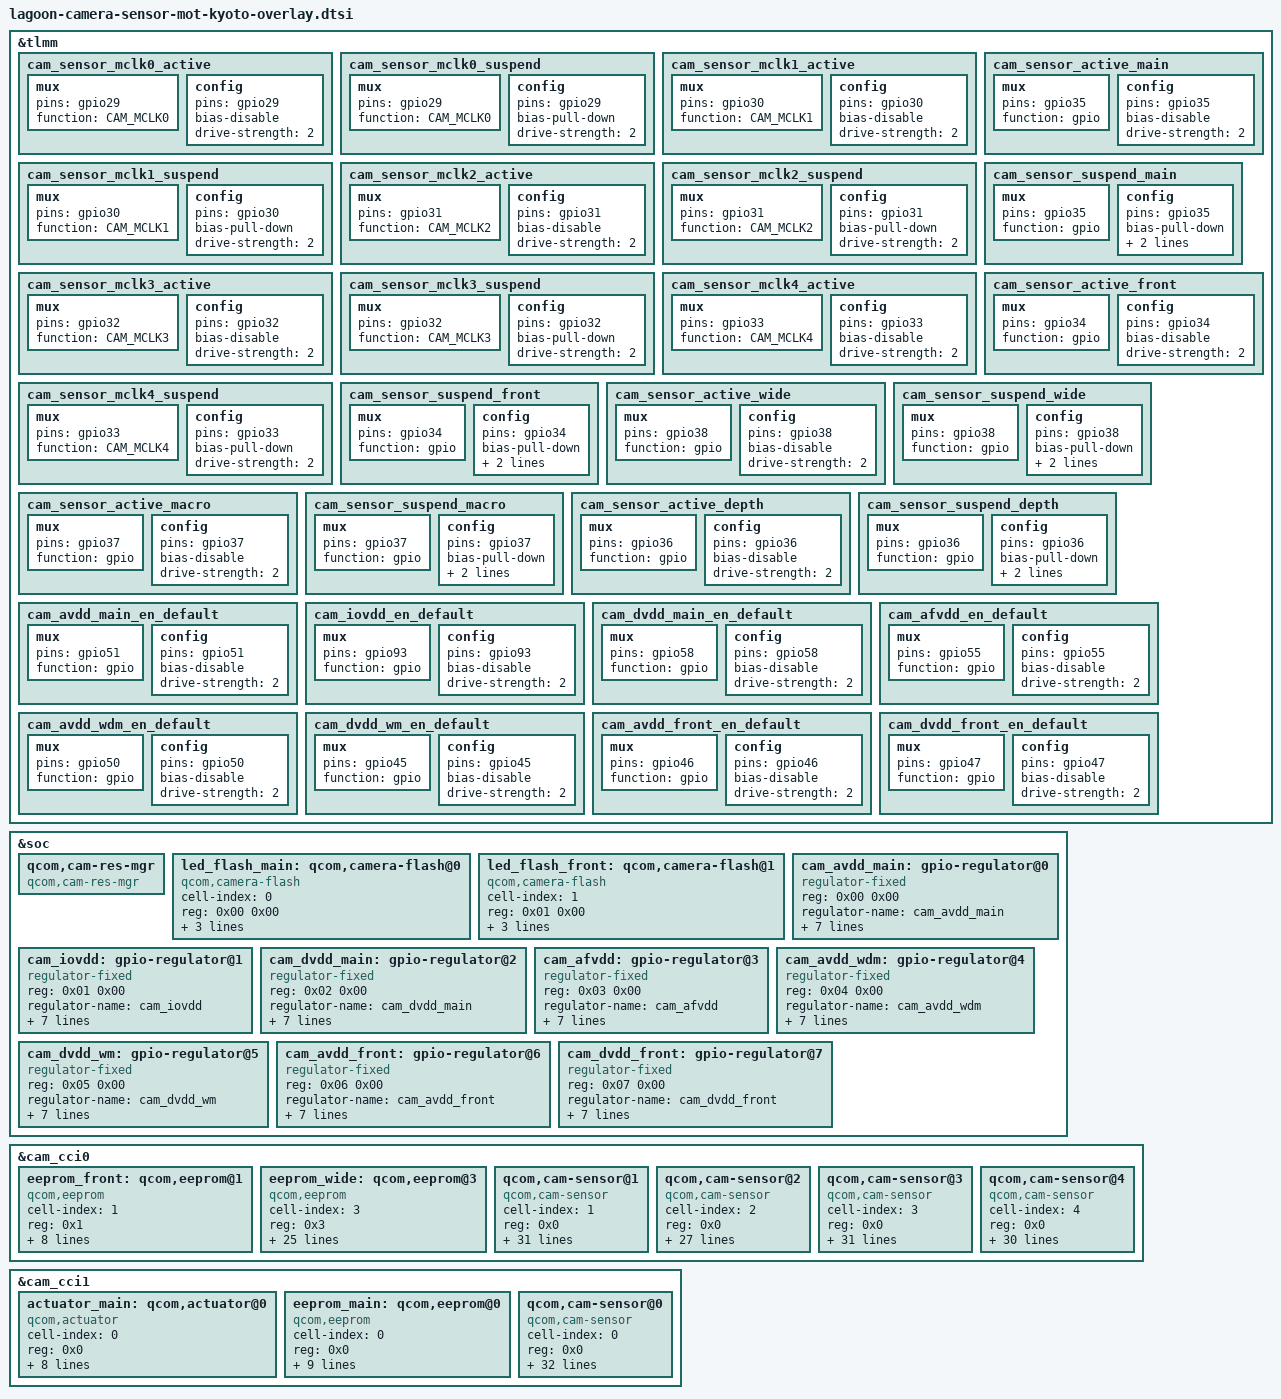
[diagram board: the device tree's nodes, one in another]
#include <dt-bindings/clock/qcom,camcc-lagoon.h>

&tlmm {
	cam_sensor_mclk0_active: cam_sensor_mclk0_active {
		/* MCLK0 */
		mux {
			pins = "gpio29";
			function = "CAM_MCLK0";
		};

		config {
			pins = "gpio29";
			bias-disable; /* No PULL */
			drive-strength = <2>; /* 2 MA */
		};
	};

	cam_sensor_mclk0_suspend: cam_sensor_mclk0_suspend {
		/* MCLK0 */
		mux {
			pins = "gpio29";
			function = "CAM_MCLK0";
		};

		config {
			pins = "gpio29";
			bias-pull-down; /* PULL DOWN */
			drive-strength = <2>; /* 2 MA */
		};
	};

	cam_sensor_mclk1_active: cam_sensor_mclk1_active {
		/* MCLK1 */
		mux {
			pins = "gpio30";
			function = "CAM_MCLK1";
		};

		config {
			pins = "gpio30";
			bias-disable; /* No PULL */
			drive-strength = <2>; /* 2 MA */
		};
	};

	cam_sensor_mclk1_suspend: cam_sensor_mclk1_suspend {
		/* MCLK1 */
		mux {
			pins = "gpio30";
			function = "CAM_MCLK1";
		};

		config {
			pins = "gpio30";
			bias-pull-down; /* PULL DOWN */
			drive-strength = <2>; /* 2 MA */
		};
	};

	cam_sensor_mclk2_active: cam_sensor_mclk2_active {
		/* MCLK2 */
		mux {
			pins = "gpio31";
			function = "CAM_MCLK2";
		};

		config {
			pins = "gpio31";
			bias-disable; /* No PULL */
			drive-strength = <2>; /* 2 MA */
		};
	};

	cam_sensor_mclk2_suspend: cam_sensor_mclk2_suspend {
		/* MCLK2 */
		mux {
			pins = "gpio31";
			function = "CAM_MCLK2";
		};

		config {
			pins = "gpio31";
			bias-pull-down; /* PULL DOWN */
			drive-strength = <2>; /* 2 MA */
		};
	};

	cam_sensor_mclk3_active: cam_sensor_mclk3_active {
		/* MCLK3 */
		mux {
			pins = "gpio32";
			function = "CAM_MCLK3";
		};

		config {
			pins = "gpio32";
			bias-disable; /* No PULL */
			drive-strength = <2>; /* 2 MA */
		};
	};

	cam_sensor_mclk3_suspend: cam_sensor_mclk3_suspend {
		/* MCLK3 */
		mux {
			pins = "gpio32";
			function = "CAM_MCLK3";
		};

		config {
			pins = "gpio32";
			bias-pull-down; /* PULL DOWN */
			drive-strength = <2>; /* 2 MA */
		};
	};

	cam_sensor_mclk4_active: cam_sensor_mclk4_active {
		/* MCLK4 */
		mux {
			pins = "gpio33";
			function = "CAM_MCLK4";
		};

		config {
			pins = "gpio33";
			bias-disable; /* No PULL */
			drive-strength = <2>; /* 2 MA */
		};
	};

	cam_sensor_mclk4_suspend: cam_sensor_mclk4_suspend {
		/* MCLK4 */
		mux {
			pins = "gpio33";
			function = "CAM_MCLK4";
		};

		config {
			pins = "gpio33";
			bias-pull-down; /* PULL DOWN */
			drive-strength = <2>; /* 2 MA */
		};
	};

	cam_sensor_active_main: cam_sensor_active_main {
		/* ream main reset */
		mux {
			pins = "gpio35";
			function = "gpio";
		};

		config {
			pins = "gpio35";
			bias-disable; /* No PULL */
			drive-strength = <2>; /* 2 MA */
		};
	};

	cam_sensor_suspend_main: cam_sensor_suspend_main {
		/* ream main reset */
		mux {
			pins = "gpio35";
			function = "gpio";
		};

		config {
			pins = "gpio35";
			bias-pull-down; /* PULL DOWN */
			drive-strength = <2>; /* 2 MA */
			output-low;
		};
	};

	cam_sensor_active_front: cam_sensor_active_front {
		/* front reset */
		mux {
			pins = "gpio34";
			function = "gpio";
		};

		config {
			pins = "gpio34";
			bias-disable; /* No PULL */
			drive-strength = <2>; /* 2 MA */
		};
	};

	cam_sensor_suspend_front: cam_sensor_suspend_front {
		/* front reset */
		mux {
			pins = "gpio34";
			function = "gpio";
		};

		config {
			pins = "gpio34";
			bias-pull-down; /* PULL DOWN */
			drive-strength = <2>; /* 2 MA */
			output-low;
		};
	};

	cam_sensor_active_wide: cam_sensor_active_wide {
		/* rear wide reset */
		mux {
			pins = "gpio38";
			function = "gpio";
		};

		config {
			pins = "gpio38";
			bias-disable; /* No PULL */
			drive-strength = <2>; /* 2 MA */
		};
	};

	cam_sensor_suspend_wide: cam_sensor_suspend_wide {
		/* rear wide reset */
		mux {
			pins = "gpio38";
			function = "gpio";
		};

		config {
			pins = "gpio38";
			bias-pull-down; /* PULL DOWN */
			drive-strength = <2>; /* 2 MA */
			output-low;
		};
	};

	cam_sensor_active_macro: cam_sensor_active_macro {
		/* rear macro reset */
		mux {
			pins = "gpio37";
			function = "gpio";
		};

		config {
			pins = "gpio37";
			bias-disable; /* No PULL */
			drive-strength = <2>; /* 2 MA */
		};
	};

	cam_sensor_suspend_macro: cam_sensor_suspend_macro {
		/* rear macro reset */
		mux {
			pins = "gpio37";
			function = "gpio";
		};

		config {
			pins = "gpio37";
			bias-pull-down; /* PULL DOWN */
			drive-strength = <2>; /* 2 MA */
			output-low;
		};
	};

	cam_sensor_active_depth: cam_sensor_active_depth {
		/* rear depth reset */
		mux {
			pins = "gpio36";
			function = "gpio";
		};

		config {
			pins = "gpio36";
			bias-disable; /* No PULL */
			drive-strength = <2>; /* 2 MA */
		};
	};

	cam_sensor_suspend_depth: cam_sensor_suspend_depth {
		/* rear depth reset */
		mux {
			pins = "gpio36";
			function = "gpio";
		};

		config {
			pins = "gpio36";
			bias-pull-down; /* PULL DOWN */
			drive-strength = <2>; /* 2 MA */
			output-low;
		};
	};

	cam_avdd_main_en_default: cam_avdd_main_en_default {
		mux {
			pins = "gpio51";
			function = "gpio";
		};

		config {
			pins = "gpio51";
			bias-disable; /* No PULL */
			drive-strength = <2>; /* 2 MA */
		};
	};

	cam_iovdd_en_default: cam_iovdd_en_default {
		mux {
			pins = "gpio93";
			function = "gpio";
		};

		config {
			pins = "gpio93";
			bias-disable; /* No PULL */
			drive-strength = <2>; /* 2 MA */
		};
	};

	cam_dvdd_main_en_default: cam_dvdd_main_en_default {
		mux {
			pins = "gpio58";
			function = "gpio";
		};

		config {
			pins = "gpio58";
			bias-disable; /* No PULL */
			drive-strength = <2>; /* 2 MA */
		};
	};

	cam_afvdd_en_default: cam_afvdd_en_default {
		mux {
			pins = "gpio55";
			function = "gpio";
		};

		config {
			pins = "gpio55";
			bias-disable; /* No PULL */
			drive-strength = <2>; /* 2 MA */
		};
	};

	cam_avdd_wdm_en_default: cam_avdd_wdm_en_default {
		mux {
			pins = "gpio50";
			function = "gpio";
		};

		config {
			pins = "gpio50";
			bias-disable; /* No PULL */
			drive-strength = <2>; /* 2 MA */
		};
	};

	cam_dvdd_wm_en_default: cam_dvdd_wm_en_default {
		mux {
			pins = "gpio45";
			function = "gpio";
		};

		config {
			pins = "gpio45";
			bias-disable; /* No PULL */
			drive-strength = <2>; /* 2 MA */
		};
	};

	cam_avdd_front_en_default: cam_avdd_front_en_default {
		mux {
			pins = "gpio46";
			function = "gpio";
		};

		config {
			pins = "gpio46";
			bias-disable; /* No PULL */
			drive-strength = <2>; /* 2 MA */
		};
	};

	cam_dvdd_front_en_default: cam_dvdd_front_en_default {
		mux {
			pins = "gpio47";
			function = "gpio";
		};

		config {
			pins = "gpio47";
			bias-disable; /* No PULL */
			drive-strength = <2>; /* 2 MA */
		};
	};
};

&soc {
	qcom,cam-res-mgr {
		compatible = "qcom,cam-res-mgr";
		status = "ok";
	};

	led_flash_main: qcom,camera-flash@0 {
		cell-index = <0>;
		reg = <0x00 0x00>;
		compatible = "qcom,camera-flash";
		flash-source = <&pm6150l_flash0>;
		torch-source = <&pm6150l_torch0>;
		switch-source = <&pm6150l_switch0>;
		status = "ok";
	};

	led_flash_front: qcom,camera-flash@1 {
		cell-index = <1>;
		reg = <0x01 0x00>;
		compatible = "qcom,camera-flash";
		flash-source = <&pm6150l_flash1>;
		torch-source = <&pm6150l_torch1>;
		switch-source = <&pm6150l_switch1>;
		status = "ok";
	};

	cam_avdd_main: gpio-regulator@0 {
		compatible = "regulator-fixed";
		reg = <0x00 0x00>;
		regulator-name = "cam_avdd_main";
		regulator-min-microvolt = <2800000>;
		regulator-max-microvolt = <2800000>;
		regulator-enable-ramp-delay = <233>;
		enable-active-high;
		gpio = <&tlmm 51 0>;
		pinctrl-names = "default";
		pinctrl-0 = <&cam_avdd_main_en_default>;
		vin-supply = <&pm6150a_bob>;
	};

	cam_iovdd: gpio-regulator@1 {
		compatible = "regulator-fixed";
		reg = <0x01 0x00>;
		regulator-name = "cam_iovdd";
		regulator-min-microvolt = <1800000>;
		regulator-max-microvolt = <1800000>;
		regulator-enable-ramp-delay = <233>;
		enable-active-high;
		gpio = <&tlmm 93 0>;
		pinctrl-names = "default";
		pinctrl-0 = <&cam_iovdd_en_default>;
		vin-supply = <&pm6150a_bob>;
	};

	cam_dvdd_main: gpio-regulator@2 {
		compatible = "regulator-fixed";
		reg = <0x02 0x00>;
		regulator-name = "cam_dvdd_main";
		regulator-min-microvolt = <1100000>;
		regulator-max-microvolt = <1100000>;
		regulator-enable-ramp-delay = <233>;
		enable-active-high;
		gpio = <&tlmm 58 0>;
		pinctrl-names = "default";
		pinctrl-0 = <&cam_dvdd_main_en_default>;
		vin-supply = <&pm6150a_s8>;
	};

	cam_afvdd: gpio-regulator@3 {
		compatible = "regulator-fixed";
		reg = <0x03 0x00>;
		regulator-name = "cam_afvdd";
		regulator-min-microvolt = <2800000>;
		regulator-max-microvolt = <2800000>;
		regulator-enable-ramp-delay = <233>;
		enable-active-high;
		gpio = <&tlmm 55 0>;
		pinctrl-names = "default";
		pinctrl-0 = <&cam_afvdd_en_default>;
		vin-supply = <&pm6150a_bob>;
	};

	cam_avdd_wdm: gpio-regulator@4 {
		compatible = "regulator-fixed";
		reg = <0x04 0x00>;
		regulator-name = "cam_avdd_wdm";
		regulator-min-microvolt = <2800000>;
		regulator-max-microvolt = <2800000>;
		regulator-enable-ramp-delay = <233>;
		enable-active-high;
		gpio = <&tlmm 50 0>;
		pinctrl-names = "default";
		pinctrl-0 = <&cam_avdd_wdm_en_default>;
		vin-supply = <&pm6150a_bob>;
	};

	cam_dvdd_wm: gpio-regulator@5 {
		compatible = "regulator-fixed";
		reg = <0x05 0x00>;
		regulator-name = "cam_dvdd_wm";
		regulator-min-microvolt = <1200000>;
		regulator-max-microvolt = <1200000>;
		regulator-enable-ramp-delay = <233>;
		enable-active-high;
		gpio = <&tlmm 45 0>;
		pinctrl-names = "default";
		pinctrl-0 = <&cam_dvdd_wm_en_default>;
		vin-supply = <&pm6150a_s8>;
	};

	cam_avdd_front: gpio-regulator@6 {
		compatible = "regulator-fixed";
		reg = <0x06 0x00>;
		regulator-name = "cam_avdd_front";
		regulator-min-microvolt = <2800000>;
		regulator-max-microvolt = <2800000>;
		regulator-enable-ramp-delay = <233>;
		enable-active-high;
		gpio = <&tlmm 46 0>;
		pinctrl-names = "default";
		pinctrl-0 = <&cam_avdd_front_en_default>;
		vin-supply = <&pm6150a_bob>;
	};

	cam_dvdd_front: gpio-regulator@7 {
		compatible = "regulator-fixed";
		reg = <0x07 0x00>;
		regulator-name = "cam_dvdd_front";
		regulator-min-microvolt = <1200000>;
		regulator-max-microvolt = <1200000>;
		regulator-enable-ramp-delay = <233>;
		enable-active-high;
		gpio = <&tlmm 47 0>;
		pinctrl-names = "default";
		pinctrl-0 = <&cam_dvdd_front_en_default>;
		vin-supply = <&pm6150a_s8>;
	};
};

&cam_cci0 {
	eeprom_front: qcom,eeprom@1 {
		cell-index = <1>;
		reg = <0x1>;
		compatible = "qcom,eeprom";
		cam_vio-supply = <&cam_iovdd>;
		regulator-names = "cam_vio";
		rgltr-cntrl-support;
		rgltr-min-voltage = <1800000>;
		rgltr-max-voltage = <1800000>;
		rgltr-load-current = <0>;
		cci-device = <0>;
		cci-master = <0>;
		status = "ok";
	};
	/*wide eeprom*/
	eeprom_wide: qcom,eeprom@3 {
		cell-index = <3>;
		reg = <0x3>;
		compatible = "qcom,eeprom";
		cam_vio-supply = <&cam_iovdd>;
		cam_vana-supply = <&cam_avdd_wdm>;
		cam_vdig-supply = <&cam_dvdd_wm>;
		cam_clk-supply = <&cam_cc_titan_top_gdsc>;
		regulator-names = "cam_vio", "cam_vana", "cam_vdig",
			"cam_clk";
		rgltr-cntrl-support;
		rgltr-min-voltage = <1800000 2800000 1200000 0>;
		rgltr-max-voltage = <1800000 2800000 1200000 0>;
		rgltr-load-current = <0 2000000 120000 0>;
		gpio-no-mux = <0>;
		pinctrl-names = "cam_default", "cam_suspend";
		pinctrl-0 = <&cam_sensor_mclk4_active
				&cam_sensor_active_wide>;
		pinctrl-1 = <&cam_sensor_mclk4_suspend
				&cam_sensor_suspend_wide>;
		gpios = <&tlmm 33 0>,
			<&tlmm 38 0>;
		gpio-reset = <1>;
		gpio-req-tbl-num = <0 1>;
		gpio-req-tbl-flags = <1 0>;
		gpio-req-tbl-label = "CAMIF_MCLK4",
					"CAM_RESET4";
		cci-device = <0>;
		cci-master = <1>;
		status = "ok";
		clocks = <&camcc CAM_CC_MCLK4_CLK>;
		clock-names = "cam_clk";
		clock-cntl-level = "turbo";
		clock-rates = <24000000>;
	};

	/*front*/
	qcom,cam-sensor@1 {
		cell-index = <1>;
		compatible = "qcom,cam-sensor";
		reg = <0x0>;
		csiphy-sd-index = <3>;
		sensor-position-roll = <270>;
		sensor-position-pitch = <0>;
		sensor-position-yaw = <0>;
		led-flash-src = <&led_flash_front>;
		eeprom-src = <&eeprom_front>;
		cam_vio-supply = <&cam_iovdd>;
		cam_vana-supply = <&cam_avdd_front>;
		cam_vdig-supply = <&cam_dvdd_front>;
		cam_clk-supply = <&cam_cc_titan_top_gdsc>;
		regulator-names = "cam_vio", "cam_vana", "cam_vdig",
			"cam_clk";
		rgltr-cntrl-support;
		rgltr-min-voltage = <1800000 2800000 1200000 0>;
		rgltr-max-voltage = <1800000 2800000 1200000 0>;
		rgltr-load-current = <0 2000000 120000 0>;
		gpio-no-mux = <0>;
		pinctrl-names = "cam_default", "cam_suspend";
		pinctrl-0 = <&cam_sensor_mclk2_active
				&cam_sensor_active_front>;
		pinctrl-1 = <&cam_sensor_mclk2_suspend
				&cam_sensor_suspend_front>;
		gpios = <&tlmm 31 0>,
			<&tlmm 34 0>;
		gpio-reset = <1>;
		gpio-req-tbl-num = <0 1>;
		gpio-req-tbl-flags = <1 0>;
		gpio-req-tbl-label = "CAMIF_MCLK2",
					"CAM_RESET2";
		cci-device = <0>;
		cci-master = <0>;
		status = "ok";
		clocks = <&camcc CAM_CC_MCLK2_CLK>;
		clock-names = "cam_clk";
		clock-cntl-level = "turbo";
		clock-rates = <24000000>;
	};
	/*depth*/
	qcom,cam-sensor@2 {
		cell-index = <2>;
		compatible = "qcom,cam-sensor";
		reg = <0x0>;
		csiphy-sd-index = <2>;
		sensor-position-roll = <90>;
		sensor-position-pitch = <0>;
		sensor-position-yaw = <180>;
		cam_vio-supply = <&cam_iovdd>;
		cam_vana-supply = <&cam_avdd_wdm>;
		cam_clk-supply = <&cam_cc_titan_top_gdsc>;
		regulator-names = "cam_vio", "cam_vana", "cam_clk";
		rgltr-cntrl-support;
		rgltr-min-voltage = <1800000 2800000 0>;
		rgltr-max-voltage = <1800000 2800000 0>;
		rgltr-load-current = <0 2000000 0>;
		gpio-no-mux = <0>;
		pinctrl-names = "cam_default", "cam_suspend";
		pinctrl-0 = <&cam_sensor_mclk1_active
				&cam_sensor_active_depth>;
		pinctrl-1 = <&cam_sensor_mclk1_suspend
				&cam_sensor_suspend_depth>;
		gpios = <&tlmm 30 0>,
			<&tlmm 36 0>;
		gpio-reset = <1>;
		gpio-req-tbl-num = <0 1>;
		gpio-req-tbl-flags = <1 0>;
		gpio-req-tbl-label = "CAMIF_MCLK1",
					"CAM_RESET1";
		cci-device = <0>;
		cci-master = <0>;
		status = "ok";
		clocks = <&camcc CAM_CC_MCLK1_CLK>;
		clock-names = "cam_clk";
		clock-cntl-level = "turbo";
		clock-rates = <24000000>;
	};
	/*wide*/
	qcom,cam-sensor@3 {
		cell-index = <3>;
		compatible = "qcom,cam-sensor";
		reg = <0x0>;
		csiphy-sd-index = <0>;
		sensor-position-roll = <90>;
		sensor-position-pitch = <0>;
		sensor-position-yaw = <180>;
		eeprom-src = <&eeprom_wide>;
		led-flash-src = <&led_flash_main>;
		cam_vio-supply = <&cam_iovdd>;
		cam_vana-supply = <&cam_avdd_wdm>;
		cam_vdig-supply = <&cam_dvdd_wm>;
		cam_clk-supply = <&cam_cc_titan_top_gdsc>;
		regulator-names = "cam_vio", "cam_vana", "cam_vdig",
			"cam_clk";
		rgltr-cntrl-support;
		rgltr-min-voltage = <1800000 2800000 1200000 0>;
		rgltr-max-voltage = <1800000 2800000 1200000 0>;
		rgltr-load-current = <0 2000000 120000 0>;
		gpio-no-mux = <0>;
		pinctrl-names = "cam_default", "cam_suspend";
		pinctrl-0 = <&cam_sensor_mclk4_active
				&cam_sensor_active_wide>;
		pinctrl-1 = <&cam_sensor_mclk4_suspend
				&cam_sensor_suspend_wide>;
		gpios = <&tlmm 33 0>,
			<&tlmm 38 0>;
		gpio-reset = <1>;
		gpio-req-tbl-num = <0 1>;
		gpio-req-tbl-flags = <1 0>;
		gpio-req-tbl-label = "CAMIF_MCLK4",
					"CAM_RESET4";
		cci-device = <0>;
		cci-master = <1>;
		status = "ok";
		clocks = <&camcc CAM_CC_MCLK4_CLK>;
		clock-names = "cam_clk";
		clock-cntl-level = "turbo";
		clock-rates = <24000000>;
	};
	/*macro*/
	qcom,cam-sensor@4 {
		cell-index = <4>;
		compatible = "qcom,cam-sensor";
		reg = <0x0>;
		csiphy-sd-index = <2>;
		sensor-position-roll = <90>;
		sensor-position-pitch = <0>;
		sensor-position-yaw = <180>;
		led-flash-src = <&led_flash_main>;
		cam_vio-supply = <&cam_iovdd>;
		cam_vana-supply = <&cam_avdd_wdm>;
		cam_vdig-supply = <&cam_dvdd_wm>;
		cam_clk-supply = <&cam_cc_titan_top_gdsc>;
		regulator-names = "cam_vio", "cam_vana", "cam_vdig",
			"cam_clk";
		rgltr-cntrl-support;
		rgltr-min-voltage = <1800000 2800000 1200000 0>;
		rgltr-max-voltage = <1800000 2800000 1200000 0>;
		rgltr-load-current = <0 2000000 120000 0>;
		gpio-no-mux = <0>;
		pinctrl-names = "cam_default", "cam_suspend";
		pinctrl-0 = <&cam_sensor_mclk3_active
				&cam_sensor_active_macro>;
		pinctrl-1 = <&cam_sensor_mclk3_suspend
				&cam_sensor_suspend_macro>;
		gpios = <&tlmm 32 0>,
			<&tlmm 37 0>;
		gpio-reset = <1>;
		gpio-req-tbl-num = <0 1>;
		gpio-req-tbl-flags = <1 0>;
		gpio-req-tbl-label = "CAMIF_MCLK3",
					"CAM_RESET3";
		cci-device = <0>;
		cci-master = <1>;
		status = "ok";
		clocks = <&camcc CAM_CC_MCLK3_CLK>;
		clock-names = "cam_clk";
		clock-cntl-level = "turbo";
		clock-rates = <24000000>;
	};
};
&cam_cci1 {
	actuator_main: qcom,actuator@0 {
		cell-index = <0>;
		reg = <0x0>;
		compatible = "qcom,actuator";
		cci-device = <1>;
		cci-master = <0>;
		cam_vaf-supply = <&cam_afvdd>;
		regulator-names = "cam_vaf";
		rgltr-cntrl-support;
		rgltr-min-voltage = <2800000>;
		rgltr-max-voltage = <2800000>;
		rgltr-load-current = <100000>;
		status = "ok";
	};

	eeprom_main: qcom,eeprom@0 {
		cell-index = <0>;
		reg = <0x0>;
		compatible = "qcom,eeprom";
		cam_vaf-supply = <&cam_afvdd>;
		cam_vio-supply = <&cam_iovdd>;
		regulator-names = "cam_vaf", "cam_vio";
		rgltr-cntrl-support;
		rgltr-min-voltage = <2800000 1800000>;
		rgltr-max-voltage = <2800000 1800000>;
		rgltr-load-current = <100000 0>;
		cci-device = <1>;
		cci-master = <0>;
		status = "ok";
	};
	/*main*/
	qcom,cam-sensor@0 {
		cell-index = <0>;
		compatible = "qcom,cam-sensor";
		reg = <0x0>;
		csiphy-sd-index = <1>;
		sensor-position-roll = <90>;
		sensor-position-pitch = <0>;
		sensor-position-yaw = <180>;
		led-flash-src = <&led_flash_main>;
		actuator-src = <&actuator_main>;
		eeprom-src = <&eeprom_main>;
		cam_vio-supply = <&cam_iovdd>;
		cam_vana-supply = <&cam_avdd_main>;
		cam_vdig-supply = <&cam_dvdd_main>;
		cam_clk-supply = <&cam_cc_titan_top_gdsc>;
		regulator-names = "cam_vio", "cam_vana", "cam_vdig",
			"cam_clk";
		rgltr-cntrl-support;
		rgltr-min-voltage = <1800000 2800000 1100000 0>;
		rgltr-max-voltage = <1800000 2800000 1100000 0>;
		rgltr-load-current = <0 2000000 100000 0>;
		gpio-no-mux = <0>;
		pinctrl-names = "cam_default", "cam_suspend";
		pinctrl-0 = <&cam_sensor_mclk0_active
				&cam_sensor_active_main>;
		pinctrl-1 = <&cam_sensor_mclk0_suspend
				&cam_sensor_suspend_main>;
		gpios = <&tlmm 29 0>,
			<&tlmm 35 0>;
		gpio-reset = <1>;
		gpio-req-tbl-num = <0 1>;
		gpio-req-tbl-flags = <1 0>;
		gpio-req-tbl-label = "CAMIF_MCLK0",
					"CAM_RESET0";
		cci-device = <1>;
		cci-master = <0>;
		status = "ok";
		clocks = <&camcc CAM_CC_MCLK0_CLK>;
		clock-names = "cam_clk";
		clock-cntl-level = "turbo";
		clock-rates = <24000000>;
	};
};

